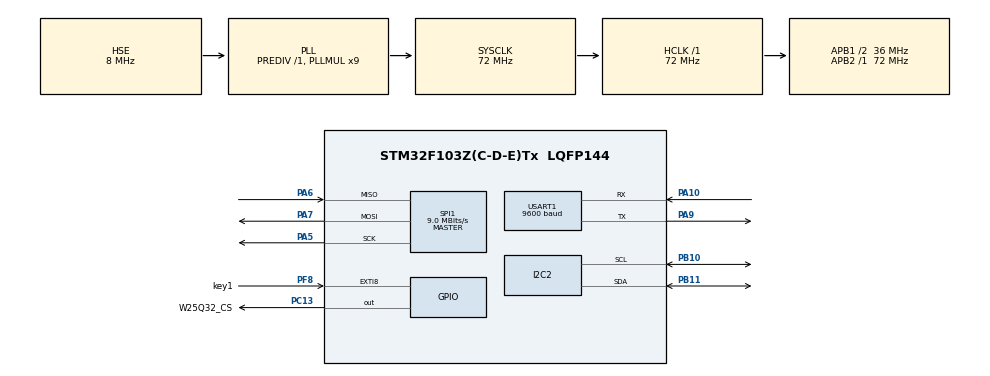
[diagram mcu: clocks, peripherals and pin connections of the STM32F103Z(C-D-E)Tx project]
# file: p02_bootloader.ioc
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Mcu.Family=STM32F1
Mcu.Name=STM32F103Z(C-D-E)Tx
Mcu.Package=LQFP144
NVIC.EXTI9_5_IRQn=true\:4\:0\:true\:false\:true\:true\:true\:true
NVIC.PriorityGroup=NVIC_PRIORITYGROUP_4
NVIC.USART1_IRQn=true\:5\:0\:true\:false\:true\:true\:true\:true
OSC_IN.Mode=HSE-External-Oscillator
OSC_IN.Signal=RCC_OSC_IN
OSC_OUT.Mode=HSE-External-Oscillator
OSC_OUT.Signal=RCC_OSC_OUT
PA10.Mode=Asynchronous
PA10.Signal=USART1_RX
PA13.Mode=Serial_Wire
PA13.Signal=SYS_JTMS-SWDIO
PA14.Mode=Serial_Wire
PA14.Signal=SYS_JTCK-SWCLK
PA5.Mode=Full_Duplex_Master
PA5.Signal=SPI1_SCK
PA6.Mode=Full_Duplex_Master
PA6.Signal=SPI1_MISO
PA7.Mode=Full_Duplex_Master
PA7.Signal=SPI1_MOSI
PA9.Mode=Asynchronous
PA9.Signal=USART1_TX
PB10.Mode=I2C
PB10.Signal=I2C2_SCL
PB11.Mode=I2C
PB11.Signal=I2C2_SDA
PC13-TAMPER-RTC.GPIO_Label=W25Q32_CS
PC13-TAMPER-RTC.GPIO_Speed=GPIO_SPEED_FREQ_HIGH
PC13-TAMPER-RTC.PinState=GPIO_PIN_SET
PC13-TAMPER-RTC.Signal=GPIO_Output
PC14-OSC32_IN.Mode=LSE-External-Oscillator
PC14-OSC32_IN.Signal=RCC_OSC32_IN
PC15-OSC32_OUT.Mode=LSE-External-Oscillator
PC15-OSC32_OUT.Signal=RCC_OSC32_OUT
PF8.GPIO_Label=key1
PF8.GPIO_ModeDefaultEXTI=GPIO_MODE_IT_FALLING
PF8.GPIO_PuPd=GPIO_PULLUP
PF8.Signal=GPXTI8
ProjectManager.HeapSize=0x200
ProjectManager.StackSize=0x400
ProjectManager.TargetToolchain=MDK-ARM V5.32
RCC.AHBFreq_Value=72000000
RCC.APB1CLKDivider=RCC_HCLK_DIV2
RCC.APB1Freq_Value=36000000
RCC.APB1TimFreq_Value=72000000
RCC.APB2Freq_Value=72000000
RCC.APB2TimFreq_Value=72000000
RCC.HCLKFreq_Value=72000000
RCC.PLLMUL=RCC_PLL_MUL9
RCC.PLLSourceVirtual=RCC_PLLSOURCE_HSE
RCC.SYSCLKFreq_VALUE=72000000
RCC.SYSCLKSource=RCC_SYSCLKSOURCE_PLLCLK
RCC.USBFreq_Value=72000000
SPI1.BaudRatePrescaler=SPI_BAUDRATEPRESCALER_8
SPI1.CalculateBaudRate=9.0 MBits/s
SPI1.Direction=SPI_DIRECTION_2LINES
SPI1.Mode=SPI_MODE_MASTER
SPI1.VirtualType=VM_MASTER
USART1.BaudRate=9600
USART1.VirtualMode=VM_ASYNC
board=custom

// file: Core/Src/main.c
/* USER CODE BEGIN Header */
/**
 ******************************************************************************
 * @file           : main.c
 * @brief          : Main program body
 ******************************************************************************
 * @attention
 *
 * Copyright (c) 2026 STMicroelectronics.
 * All rights reserved.
 *
 * This software is licensed under terms that can be found in the LICENSE file
 * in the root directory of this software component.
 * If no LICENSE file comes with this software, it is provided AS-IS.
 *
 ******************************************************************************
 */
/* USER CODE END Header */
#include "main.h"
#include "i2c.h"
#include "spi.h"
#include "usart.h"
#include "gpio.h"

/* USER CODE BEGIN Includes */
#include "Int_bootloader.h"
#include "app_bootloader.h"
#include "Int_w24c02.h"
#include "Int_w25q32.h"
extern uint8_t is_bootloader;
extern uint32_t uart_rec_full_len;
/* USER CODE END Includes */

void SystemClock_Config(void);

int main(void)
{

  /* MCU Configuration--------------------------------------------------------*/

  /* Reset of all peripherals, Initializes the Flash interface and the Systick. */
  HAL_Init();

  /* Configure the system clock */
  SystemClock_Config();

  /* Initialize all configured peripherals */
  MX_GPIO_Init();
  MX_USART1_UART_Init();
  MX_I2C2_Init();
  MX_SPI1_Init();
  /* USER CODE BEGIN 2 */
  // Int_Bootloader();

  // App_bootloader_init();
  // 1. 检查更新状态
  App_bootloader_check_update();
  // 2. 是否进入默认程序
  App_bootloader_check_default();
  // 3. 执行更新操作
  App_bootloader_update();
  // 4. 跳转到应用程序
  App_bootloader_jump_app();

  // 测试EEPROM
  // 写入数据后，等5ms以上才能读取，否则读不到
  // Int_w24c02_write_byte(0x00, 'c');
  // HAL_Delay(5);
  // uint8_t data = Int_w24c02_read_byte(0x00);
  // printf("read data: %c\n", data);

  // 2 写入的数据超过1页，会从头开始写
  // Int_w24c02_write_bytes(0x01, (uint8_t *)"123456789012345678910", 21);
  // HAL_Delay(5);
  // // 读取写入的数据
  // uint8_t read_data[21];
  // Int_w24c02_read_bytes(0x01, read_data, 21);
  // printf("read data: %s\n", read_data);

  // uint8_t mf_id;
  // uint16_t dev_id;
  // Int_w25q32_read_id(&mf_id, &dev_id);
  // printf("mf_id: %02x, dev_id: %04x\n", mf_id, dev_id);
  /* USER CODE END 2 */

  /* Infinite loop */
  while (1)
  {

    /* USER CODE BEGIN 3 */
    // App_bootloader_work();
  }
  /* USER CODE END 3 */
}

void SystemClock_Config(void)
{
  RCC_OscInitTypeDef RCC_OscInitStruct = {0};
  RCC_ClkInitTypeDef RCC_ClkInitStruct = {0};

  /** Initializes the RCC Oscillators according to the specified parameters
   * in the RCC_OscInitTypeDef structure.
   */
  RCC_OscInitStruct.OscillatorType = RCC_OSCILLATORTYPE_HSE;
  RCC_OscInitStruct.HSEState = RCC_HSE_ON;
  RCC_OscInitStruct.HSEPredivValue = RCC_HSE_PREDIV_DIV1;
  RCC_OscInitStruct.HSIState = RCC_HSI_ON;
  RCC_OscInitStruct.PLL.PLLState = RCC_PLL_ON;
  RCC_OscInitStruct.PLL.PLLSource = RCC_PLLSOURCE_HSE;
  RCC_OscInitStruct.PLL.PLLMUL = RCC_PLL_MUL9;
  if (HAL_RCC_OscConfig(&RCC_OscInitStruct) != HAL_OK)
  {
    Error_Handler();
  }

  /** Initializes the CPU, AHB and APB buses clocks
   */
  RCC_ClkInitStruct.ClockType = RCC_CLOCKTYPE_HCLK | RCC_CLOCKTYPE_SYSCLK | RCC_CLOCKTYPE_PCLK1 | RCC_CLOCKTYPE_PCLK2;
  RCC_ClkInitStruct.SYSCLKSource = RCC_SYSCLKSOURCE_PLLCLK;
  RCC_ClkInitStruct.AHBCLKDivider = RCC_SYSCLK_DIV1;
  RCC_ClkInitStruct.APB1CLKDivider = RCC_HCLK_DIV2;
  RCC_ClkInitStruct.APB2CLKDivider = RCC_HCLK_DIV1;

  if (HAL_RCC_ClockConfig(&RCC_ClkInitStruct, FLASH_LATENCY_2) != HAL_OK)
  {
    Error_Handler();
  }
}

void Error_Handler(void)
{
  __disable_irq();
  while (1)
  {
  }
}
